VERSION "created by canmatrix"

NS_ :

BS_:

BU_:

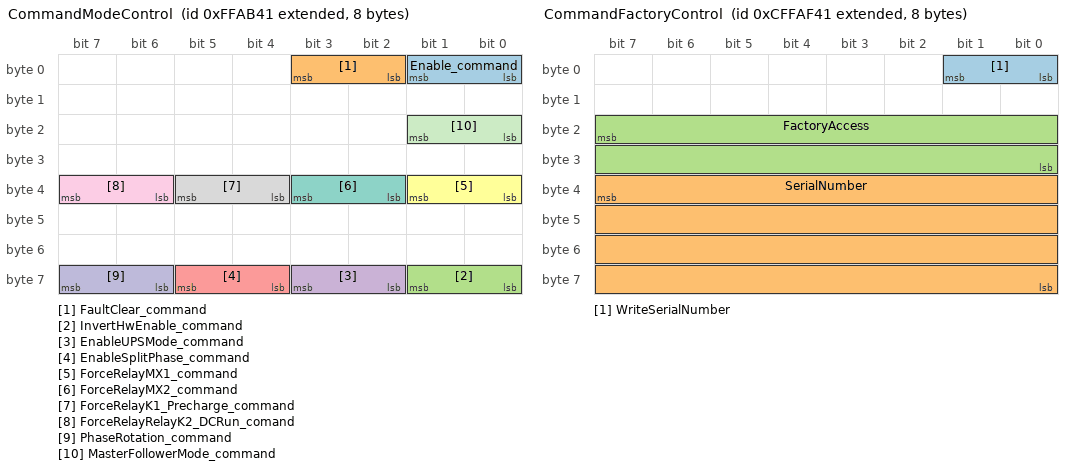
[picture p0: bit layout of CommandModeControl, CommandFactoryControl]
BO_ 2164239169 CommandModeControl: 8 Vector__XXX
 SG_ Enable_command : 1|2@0+ (1,0) [0|1] "" Vector__XXX
 SG_ FaultClear_command : 3|2@0+ (1,0) [0|1] "" Vector__XXX
 SG_ InvertHwEnable_command : 57|2@0+ (1,0) [0|1] "" Vector__XXX
 SG_ EnableUPSMode_command : 59|2@0+ (1,0) [0|1] "" Vector__XXX
 SG_ EnableSplitPhase_command : 61|2@0+ (1,0) [0|1] "" Vector__XXX
 SG_ ForceRelayMX1_command : 33|2@0+ (1,0) [0|1] "" Vector__XXX
 SG_ ForceRelayMX2_command : 35|2@0+ (1,0) [0|1] "" Vector__XXX
 SG_ ForceRelayK1_Precharge_command : 37|2@0+ (1,0) [0|1] "" Vector__XXX
 SG_ ForceRelayRelayK2_DCRun_comand : 39|2@0+ (1,0) [0|1] "" Vector__XXX
 SG_ PhaseRotation_command : 63|2@0+ (1,0) [0|1] "" Vector__XXX
 SG_ MasterFollowerMode_command : 17|2@0+ (1,0) [0|1] "" Vector__XXX

BO_ 2365566017 CommandPower: 8 Vector__XXX
 SG_ "RealPower command" : 7|32@0- (1,0) [-90000|90000] "W" Vector__XXX
 SG_ ReactivePower_command : 39|32@0- (1,0) [-90000|90000] "VA" Vector__XXX

BO_ 2365566529 CommandVF: 8 Vector__XXX
 SG_ Voltage_command : 7|16@0+ (0.1,0) [10|500] "Vrms" Vector__XXX
 SG_ Frequency_command : 23|16@0+ (0.1,0) [45|65] "Hz" Vector__XXX

BO_ 2365573878 MasterMeasuredPower: 8 Vector__XXX
 SG_ RealPower_measured : 7|32@0- (1,0) [0|1] "W" Vector__XXX
 SG_ ReactivePower_measured : 39|32@0- (1,0) [0|1] "VA" Vector__XXX

BO_ 2365566785 CommandFactoryControl: 8 Vector__XXX
 SG_ WriteSerialNumber : 1|2@0+ (1,0) [0|1] "" Vector__XXX
 SG_ SerialNumber : 39|32@0+ (1,0) [0|1] "" Vector__XXX
 SG_ FactoryAccess : 23|16@0+ (1,0) [0|1] "" Vector__XXX

BO_ 2365565505 CommandSetNVParam: 8 Vector__XXX
 SG_ CommandSetNVParam_MUX M  : 7|16@0- (1,0) [0|1] "" Vector__XXX
 SG_ Dummy m0  : 23|16@0+ (1,0) [0|1] "" Vector__XXX
 SG_ VUnder50pct m1  : 23|16@0+ (1,0) [1|30000] "ms" Vector__XXX
 SG_ V50to88pct m1  : 39|16@0+ (1,0) [1|30000] "ms" Vector__XXX
 SG_ V110to120pct m1  : 55|16@0+ (1,0) [1|30000] "ms" Vector__XXX
 SG_ VOver120 m2  : 23|16@0+ (1,0) [1|30000] "" Vector__XXX
 SG_ FreqHi m3  : 23|16@0+ (0.1,0) [40|70] "Hz" Vector__XXX
 SG_ FreqLo m3  : 39|16@0+ (0.1,0) [40|70] "Hz" Vector__XXX
 SG_ FreqVeryLo m3  : 55|16@0+ (0.1,0) [40|70] "Hz" Vector__XXX
 SG_ FreqVeryLo m4  : 23|16@0+ (1,0) [160|160] "ms" Vector__XXX
 SG_ FreqLo m4  : 39|16@0+ (1,0) [1|30000] "ms" Vector__XXX
 SG_ FreqHi m4  : 55|16@0+ (1,0) [160|160] "ms" Vector__XXX
 SG_ NodeID m5  : 23|8@0+ (1,0) [0|247] "" Vector__XXX
 SG_ SA_Mask m5  : 31|8@0+ (1,0) [0|1] "" Vector__XXX
 SG_ Baudrate m5  : 39|4@0+ (1,0) [0|3] "" Vector__XXX
 SG_ ThermalOverload m6  : 17|2@0+ (1,0) [0|1] "" Vector__XXX
 SG_ MX1Open m7  : 23|16@0+ (1,0) [0|5000] "ms" Vector__XXX
 SG_ MX1Close m7  : 39|16@0+ (1,0) [0|2000] "ms" Vector__XXX
 SG_ MX2Open m7  : 55|16@0+ (1,0) [0|1] "ms" Vector__XXX
 SG_ MX2Close m8  : 23|16@0+ (1,0) [0|2000] "ms" Vector__XXX
 SG_ K1Open m8  : 39|16@0+ (1,0) [0|2000] "ms" Vector__XXX
 SG_ K1Close m8  : 55|16@0+ (1,0) [0|2000] "ms" Vector__XXX
 SG_ K2Open m10  : 23|16@0+ (1,0) [0|2000] "ms" Vector__XXX
 SG_ K2Close m10  : 39|16@0+ (1,0) [0|2000] "ms" Vector__XXX

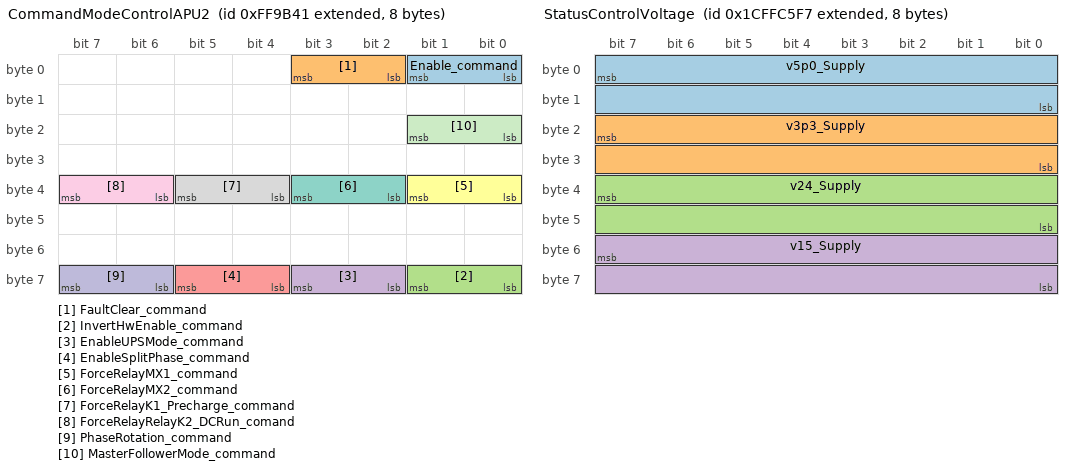
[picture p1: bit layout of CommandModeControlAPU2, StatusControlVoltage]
BO_ 2164235073 CommandModeControlAPU2: 8 Vector__XXX
 SG_ Enable_command : 1|2@0+ (1,0) [0|1] "" Vector__XXX
 SG_ FaultClear_command : 3|2@0+ (1,0) [0|1] "" Vector__XXX
 SG_ InvertHwEnable_command : 57|2@0+ (1,0) [0|1] "" Vector__XXX
 SG_ EnableUPSMode_command : 59|2@0+ (1,0) [0|1] "" Vector__XXX
 SG_ EnableSplitPhase_command : 61|2@0+ (1,0) [0|1] "" Vector__XXX
 SG_ ForceRelayMX1_command : 33|2@0+ (1,0) [0|1] "" Vector__XXX
 SG_ ForceRelayMX2_command : 35|2@0+ (1,0) [0|1] "" Vector__XXX
 SG_ ForceRelayK1_Precharge_command : 37|2@0+ (1,0) [0|1] "" Vector__XXX
 SG_ ForceRelayRelayK2_DCRun_comand : 39|2@0+ (1,0) [0|1] "" Vector__XXX
 SG_ PhaseRotation_command : 63|2@0+ (1,0) [0|1] "" Vector__XXX
 SG_ MasterFollowerMode_command : 17|2@0+ (1,0) [0|1] "" Vector__XXX

BO_ 2365561921 CommandPowerAPU2: 8 Vector__XXX
 SG_ RealPower_command : 7|32@0- (1,0) [-90000|90000] "W" Vector__XXX
 SG_ ReactivePower_command : 39|32@0- (1,0) [-90000|90000] "VA" Vector__XXX

BO_ 2365562433 CommandVFAPU2: 8 Vector__XXX
 SG_ Voltage_command : 7|16@0+ (0.1,0) [10|500] "Vrms" Vector__XXX
 SG_ Frequency_command : 23|16@0+ (0.1,0) [45|65] "Hz" Vector__XXX

BO_ 2365573879 MasterMeasuredPowerAPU2: 8 Vector__XXX
 SG_ RealPower_measured : 7|32@0- (1,0) [0|1] "W" Vector__XXX
 SG_ ReactivePower_measured : 39|32@0- (1,0) [0|1] "VA" Vector__XXX

BO_ 2365573879 StatusMeasuredPower: 8 Vector__XXX
 SG_ RealPower_measured : 7|32@0- (1,0) [0|1] "W" Vector__XXX
 SG_ ReactivePower_measured : 39|32@0- (1,0) [0|1] "VA" Vector__XXX

BO_ 2566898935 StatusCommandedPower: 8 Vector__XXX
 SG_ RealPower_echo : 7|32@0- (1,0) [0|1] "W" Vector__XXX
 SG_ ReactivePower_echo : 39|32@0- (1,0) [0|1] "VA" Vector__XXX

BO_ 2365572087 StatusBits: 8 Vector__XXX
 SG_ State_status : 3|4@0+ (1,0) [0|7] "" Vector__XXX
 SG_ MX2Permissive_status : 19|2@0+ (1,0) [0|1] "" Vector__XXX
 SG_ PowerAvailAC_status : 11|2@0+ (1,0) [0|1] "" Vector__XXX
 SG_ PowerAvailDC_status : 13|2@0+ (1,0) [0|1] "" Vector__XXX
 SG_ PowerCircuitEnabled_status : 15|2@0+ (1,0) [0|1] "" Vector__XXX
 SG_ HardwareEnable_status : 9|2@0+ (1,0) [0|1] "" Vector__XXX
 SG_ Enable_echo : 5|2@0+ (1,0) [0|1] "" Vector__XXX
 SG_ FaultClr_echo : 7|2@0+ (1,0) [0|1] "" Vector__XXX
 SG_ MessageValidModeControl_status : 25|2@0+ (1,0) [0|1] "" Vector__XXX
 SG_ MX1Permissive_status : 17|2@0+ (1,0) [0|1] "" Vector__XXX
 SG_ K2DCRunPermissive_status : 23|2@0+ (1,0) [0|1] "" Vector__XXX
 SG_ K1PrechargePermissive_status : 21|2@0+ (1,0) [0|1] "" Vector__XXX
 SG_ MessageValidPowerCMD_status : 27|2@0+ (1,0) [0|1] "" Vector__XXX
 SG_ MessageValidVF_status : 29|2@0+ (1,0) [0|1] "" Vector__XXX
 SG_ CANbus_status : 31|2@0+ (1,0) [0|1] "" Vector__XXX
 SG_ EnableUPSMode_echo : 33|2@0+ (1,0) [0|1] "" Vector__XXX
 SG_ EnableSplitPhase_echo : 35|2@0+ (1,0) [0|1] "" Vector__XXX
 SG_ PhaseRotation_status : 37|2@0+ (1,0) [0|1] "" Vector__XXX
 SG_ LineVoltageDetected_status : 39|2@0+ (1,0) [0|1] "" Vector__XXX
 SG_ PhaseRotation_echo : 41|2@0+ (1,0) [0|1] "" Vector__XXX

BO_ 2634008055 StatusControlVoltage: 8 Vector__XXX
 SG_ v5p0_Supply : 7|16@0- (0.01,0) [0|1] "V" Vector__XXX
 SG_ v3p3_Supply : 23|16@0- (0.01,0) [0|1] "V" Vector__XXX
 SG_ v24_Supply : 39|16@0- (0.01,0) [0|1] "V" Vector__XXX
 SG_ v15_Supply : 55|16@0- (0.01,0) [0|1] "V" Vector__XXX

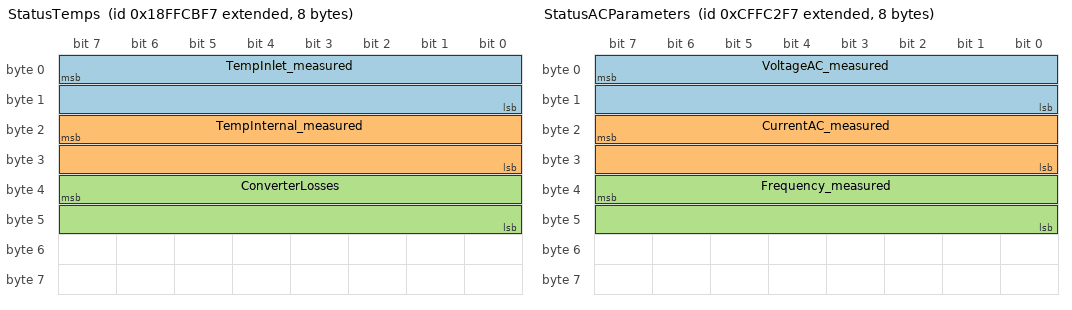
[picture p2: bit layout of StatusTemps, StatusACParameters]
BO_ 2566900727 StatusTemps: 8 Vector__XXX
 SG_ TempInlet_measured : 7|16@0- (0.1,0) [0|1] "C" Vector__XXX
 SG_ TempInternal_measured : 23|16@0- (0.1,0) [0|1] "C" Vector__XXX
 SG_ ConverterLosses : 39|16@0+ (1,0) [0|1] "W" Vector__XXX

BO_ 2365573367 StatusFaults: 8 Vector__XXX
 SG_ BridgeAVoltageOk_status : 59|1@0+ (1,0) [0|1] "" Vector__XXX
 SG_ OvercurrentAC_status : 3|2@0+ (1,0) [0|1] "" Vector__XXX
 SG_ BridgeBVoltageOk_status : 43|1@0+ (1,0) [0|1] "" Vector__XXX
 SG_ OvervoltageDC_status : 9|2@0+ (1,0) [0|1] "" Vector__XXX
 SG_ OvertempPowerDevice_status : 15|2@0+ (1,0) [0|1] "" Vector__XXX
 SG_ OvertempInternal_status : 13|2@0+ (1,0) [0|1] "" Vector__XXX
 SG_ LossValidControlMessage_status : 23|4@0+ (1,0) [0|1] "" Vector__XXX
 SG_ UndervoltageDC_status : 11|2@0+ (1,0) [0|1] "" Vector__XXX
 SG_ ControlHardwareFail_status : 19|4@0+ (1,0) [0|1] "" Vector__XXX
 SG_ OvercurrentDC_status : 7|2@0+ (1,0) [0|1] "" Vector__XXX
 SG_ GeneralFault_status : 1|2@0+ (1,0) [0|1] "" Vector__XXX
 SG_ LossOfAC_status : 5|2@0+ (1,0) [0|1] "" Vector__XXX
 SG_ EStopShutdown_status : 25|2@0+ (1,0) [0|1] "" Vector__XXX
 SG_ BridgeAFault_status : 58|3@0+ (1,0) [0|1] "" Vector__XXX
 SG_ BridgeBFault_status : 42|3@0+ (1,0) [0|1] "" Vector__XXX
 SG_ IllegalTransition_status : 27|2@0+ (1,0) [0|1] "" Vector__XXX
 SG_ InvalidEEHeader_status : 29|2@0+ (1,0) [0|1] "" Vector__XXX
 SG_ InvalidEESection_status : 31|2@0+ (1,0) [0|1] "" Vector__XXX
 SG_ ThermalOverload : 33|2@0+ (1,0) [0|1] "" Vector__XXX

BO_ 2365571831 StatusACParameters: 8 Vector__XXX
 SG_ VoltageAC_measured : 7|16@0- (0.1,0) [0|1] "V" Vector__XXX
 SG_ CurrentAC_measured : 23|16@0- (1,0) [0|1] "A" Vector__XXX
 SG_ Frequency_measured : 39|16@0- (0.1,0) [0|1] "Hz" Vector__XXX

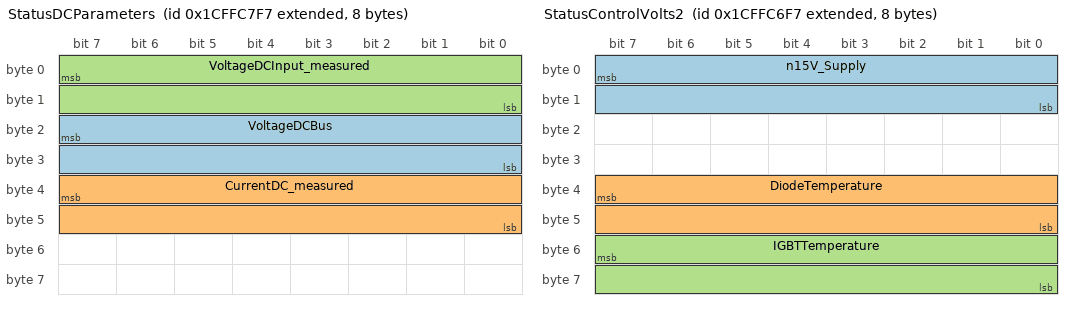
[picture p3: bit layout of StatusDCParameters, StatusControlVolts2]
BO_ 2634008567 StatusDCParameters: 8 Vector__XXX
 SG_ VoltageDCBus : 23|16@0- (1,0) [0|1] "V" Vector__XXX
 SG_ CurrentDC_measured : 39|16@0- (1,0) [0|1] "A" Vector__XXX
 SG_ VoltageDCInput_measured : 7|16@0- (1,0) [0|1] "V" Vector__XXX

BO_ 2634008311 StatusControlVolts2: 8 Vector__XXX
 SG_ n15V_Supply : 7|16@0- (0.01,0) [0|1] "V" Vector__XXX
 SG_ DiodeTemperature : 39|16@0+ (1,0) [0|1] "C" Vector__XXX
 SG_ IGBTTemperature : 55|16@0+ (1,0) [0|1] "C" Vector__XXX

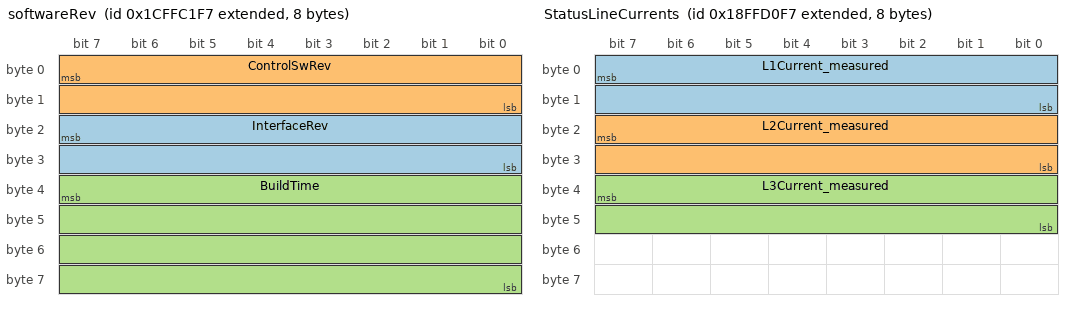
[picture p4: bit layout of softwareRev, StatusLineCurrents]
BO_ 2634007031 softwareRev: 8 Vector__XXX
 SG_ InterfaceRev : 23|16@0+ (0.01,0) [0|1] "" Vector__XXX
 SG_ ControlSwRev : 7|16@0+ (0.01,0) [0|1] "" Vector__XXX
 SG_ BuildTime : 39|32@0+ (1,0) [0|1] "" Vector__XXX

BO_ 2566900215 StatusCommandVF: 8 Vector__XXX
 SG_ Voltage_echo : 7|16@0+ (0.1,0) [0|1] "Vrms" Vector__XXX
 SG_ Frequency_echo : 23|16@0+ (0.1,0) [0|1] "Hz" Vector__XXX

BO_ 2634009847 serialNumber: 8 Vector__XXX
 SG_ SerialNumber : 7|32@0+ (1,0) [0|1] "" Vector__XXX

BO_ 2634010103 softwareRevHash: 8 Vector__XXX
 SG_ Hash : 7|28@0+ (1,0) [0|1] "" Vector__XXX

BO_ 2634000887 StatusNVParam: 8 Vector__XXX
 SG_ StatusNVParam_MUX M  : 7|16@0- (1,0) [0|1] "" Vector__XXX
 SG_ Dummy m0  : 23|16@0+ (1,0) [5|10] "" Vector__XXX
 SG_ VUnder50pct m1  : 23|16@0+ (1,0) [1|30000] "ms" Vector__XXX
 SG_ V50to88pct m1  : 39|16@0+ (1,0) [1|30000] "ms" Vector__XXX
 SG_ V110to120pct m1  : 55|16@0+ (1,0) [1|30000] "ms" Vector__XXX
 SG_ VOver120 m2  : 23|16@0+ (1,0) [1|30000] "" Vector__XXX
 SG_ FreqHi m3  : 23|16@0+ (0.1,0) [40|70] "Hz" Vector__XXX
 SG_ FreqLo m3  : 39|16@0+ (0.1,0) [40|70] "Hz" Vector__XXX
 SG_ FreqVeryLo m3  : 55|16@0+ (0.1,0) [40|70] "Hz" Vector__XXX
 SG_ FreqVeryLo m4  : 23|16@0+ (1,0) [160|160] "ms" Vector__XXX
 SG_ FreqLo m4  : 39|16@0+ (1,0) [1|30000] "ms" Vector__XXX
 SG_ FreqHi m4  : 55|16@0+ (1,0) [160|160] "ms" Vector__XXX
 SG_ StatusNodeID m5  : 23|8@0+ (1,0) [0|247] "" Vector__XXX
 SG_ StatusSA_Mask m5  : 31|8@0+ (1,0) [0|1] "" Vector__XXX
 SG_ StatusBaudrate m5  : 39|4@0+ (1,0) [0|3] "" Vector__XXX
 SG_ StatusThermalOverload m6  : 17|2@0+ (1,0) [0|1] "" Vector__XXX
 SG_ StatusMX1Open m7  : 23|16@0+ (1,0) [0|5000] "ms" Vector__XXX
 SG_ StatusMX1Close m7  : 39|16@0+ (1,0) [0|2000] "ms" Vector__XXX
 SG_ StatusMX2Open m7  : 55|16@0+ (1,0) [0|1] "ms" Vector__XXX
 SG_ StatusMX2Close m8  : 23|16@0+ (1,0) [0|2000] "ms" Vector__XXX
 SG_ StatusK1Open m8  : 39|16@0+ (1,0) [0|2000] "ms" Vector__XXX
 SG_ StatusK1Close m8  : 55|16@0+ (1,0) [0|2000] "ms" Vector__XXX
 SG_ StatusK2Open m9  : 23|16@0+ (1,0) [0|2000] "ms" Vector__XXX
 SG_ StatusK2Close m9  : 39|16@0+ (1,0) [0|2000] "ms" Vector__XXX

BO_ 2566902007 StatusLineCurrents: 8 Vector__XXX
 SG_ L1Current_measured : 7|16@0+ (1,0) [0|1] "A" Vector__XXX
 SG_ L2Current_measured : 23|16@0+ (1,0) [0|1] "A" Vector__XXX
 SG_ L3Current_measured : 39|16@0+ (1,0) [0|1] "A" Vector__XXX

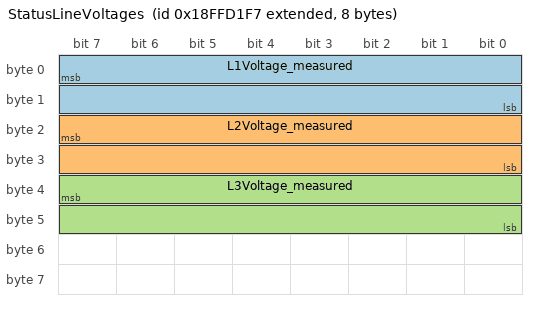
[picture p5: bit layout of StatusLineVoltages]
BO_ 2566902263 StatusLineVoltages: 8 Vector__XXX
 SG_ L1Voltage_measured : 7|16@0+ (0.1,0) [0|1] "Vrms" Vector__XXX
 SG_ L2Voltage_measured : 23|16@0+ (0.1,0) [0|1] "Vrms" Vector__XXX
 SG_ L3Voltage_measured : 39|16@0+ (0.1,0) [0|1] "Vrms" Vector__XXX

CM_ BO_ 2164239169  "Operational commands are received by the module via control bits within this message.";
CM_ BO_ 2365566017  "Sets the desired real (P) and reactive (Q) power levels for the module to follow while in the GRID FOLLOWING mode.";
CM_ BO_ 2365566529  "Sets the desired voltage and frequency for the module to produce while in the GRID FORMING mode.  In addition, while in the READY and GRID FOLLOWING modes, this message is used to set the nominal voltage levels for detection of acceptable AC line voltage.";
CM_ BO_ 2365573878  "Returns the actual measured power.";
CM_ BO_ 2365565505  "Provides access to configure non-volatile parameters.  Note that these parameters can only be set when the inverter's power stage is disabled (PowerCircuitEnabled_status in StatusBits message is 'Disabled.')";
CM_ BO_ 2164235073  "Operational commands are received by the module via control bits within this message.";
CM_ BO_ 2365561921  "Sets the desired real (P) and reactive (Q) power levels for the module to follow while in the GRID FOLLOWING mode.";
CM_ BO_ 2365562433  "Sets the desired voltage and frequency for the module to produce while in the GRID FORMING mode.  In addition, while in the READY and GRID FOLLOWING modes, this message is used to set the nominal voltage levels for detection of acceptable AC line voltage.";
CM_ BO_ 2365573879  "Returns the actual measured power.";
CM_ BO_ 2365573879  "Returns the actual measured power.";
CM_ BO_ 2566898935  "Echoes the commanded power (P&Q) as received in CommandPQ.";
CM_ BO_ 2365572087  "Bits representing the status of the power module.";
CM_ BO_ 2634008055  "Lists present voltage of each power supply on the control board (24V, 15V, 5V, and 3.3V.)";
CM_ BO_ 2566900727  "Returns the inlet water temperature to the module as well as module internal ambient temperature.";
CM_ BO_ 2365573367  "Fault bits.";
CM_ BO_ 2365571831  "RMS AC Voltage, current, and frequency measured by line A, B and C feedbacks.";
CM_ BO_ 2634008567  "Measured (boosted) DC Bus voltage, DC Current, and estimated DC Input voltage.";
CM_ BO_ 2634008311  "Present voltage of the -15V power supply on the control board.";
CM_ BO_ 2634007031  "Software revision.";
CM_ BO_ 2566900215  "Echoes the voltage and frequency commands from commandVF.";
CM_ BO_ 2634009847  "Serial number of the power module.";
CM_ BO_ 2634010103  "Unique software revision identification hashcode.";
CM_ BO_ 2634000887  "Echos back parameter values.";
CM_ BO_ 2566902007  "Measured RMS line currents.";
CM_ BO_ 2566902263  "Measured RMS line voltages.";

BA_DEF_ BO_ "GenMsgCycleTime" INT 0 65535;
BA_DEF_ SG_ "GenSigStartValue" FLOAT -3.4E+038 3.4E+038;

BA_ "GenMsgCycleTime" BO_ 2365573879 100;
BA_ "GenMsgCycleTime" BO_ 2566898935 100;
BA_ "GenMsgCycleTime" BO_ 2365572087 100;
BA_ "GenMsgCycleTime" BO_ 2634008055 100;
BA_ "GenMsgCycleTime" BO_ 2566900727 100;
BA_ "GenMsgCycleTime" BO_ 2365573367 100;
BA_ "GenMsgCycleTime" BO_ 2365571831 100;
BA_ "GenMsgCycleTime" BO_ 2634008567 100;
BA_ "GenMsgCycleTime" BO_ 2634008311 100;
BA_ "GenMsgCycleTime" BO_ 2566900215 100;
BA_ "GenMsgCycleTime" BO_ 2566902007 100;
BA_ "GenMsgCycleTime" BO_ 2566902263 100;

BA_ "GenSigStartValue" SG_ 2164239169 Enable_command 0.0;
BA_ "GenSigStartValue" SG_ 2164239169 FaultClear_command 0.0;
BA_ "GenSigStartValue" SG_ 2164239169 InvertHwEnable_command 0.0;
BA_ "GenSigStartValue" SG_ 2164239169 EnableUPSMode_command 0.0;
BA_ "GenSigStartValue" SG_ 2164239169 EnableSplitPhase_command 0.0;
BA_ "GenSigStartValue" SG_ 2164239169 ForceRelayMX1_command 0.0;
BA_ "GenSigStartValue" SG_ 2164239169 ForceRelayMX2_command 0.0;
BA_ "GenSigStartValue" SG_ 2164239169 ForceRelayK1_Precharge_command 0.0;
BA_ "GenSigStartValue" SG_ 2164239169 ForceRelayRelayK2_DCRun_comand 0.0;
BA_ "GenSigStartValue" SG_ 2164239169 PhaseRotation_command 0.0;
BA_ "GenSigStartValue" SG_ 2164239169 MasterFollowerMode_command 0.0;
BA_ "GenSigStartValue" SG_ 2365566017 "RealPower command" 0.0;
BA_ "GenSigStartValue" SG_ 2365566017 ReactivePower_command 0.0;
BA_ "GenSigStartValue" SG_ 2365566529 Voltage_command 2400.0;
BA_ "GenSigStartValue" SG_ 2365566529 Frequency_command 500.0;
BA_ "GenSigStartValue" SG_ 2365573878 RealPower_measured 0.0;
BA_ "GenSigStartValue" SG_ 2365573878 ReactivePower_measured 0.0;
BA_ "GenSigStartValue" SG_ 2365566785 WriteSerialNumber 0.0;
BA_ "GenSigStartValue" SG_ 2365566785 SerialNumber 0.0;
BA_ "GenSigStartValue" SG_ 2365566785 FactoryAccess 0.0;
BA_ "GenSigStartValue" SG_ 2365565505 Dummy 0.0;
BA_ "GenSigStartValue" SG_ 2365565505 VUnder50pct 160.0;
BA_ "GenSigStartValue" SG_ 2365565505 V50to88pct 2000.0;
BA_ "GenSigStartValue" SG_ 2365565505 V110to120pct 1000.0;
BA_ "GenSigStartValue" SG_ 2365565505 VOver120 160.0;
BA_ "GenSigStartValue" SG_ 2365565505 FreqHi 605.0;
BA_ "GenSigStartValue" SG_ 2365565505 FreqLo 598.0;
BA_ "GenSigStartValue" SG_ 2365565505 FreqVeryLo 570.0;
BA_ "GenSigStartValue" SG_ 2365565505 FreqVeryLo 160.0;
BA_ "GenSigStartValue" SG_ 2365565505 FreqLo 160.0;
BA_ "GenSigStartValue" SG_ 2365565505 FreqHi 160.0;
BA_ "GenSigStartValue" SG_ 2365565505 NodeID 247.0;
BA_ "GenSigStartValue" SG_ 2365565505 SA_Mask 65.0;
BA_ "GenSigStartValue" SG_ 2365565505 Baudrate 2.0;
BA_ "GenSigStartValue" SG_ 2365565505 ThermalOverload 0.0;
BA_ "GenSigStartValue" SG_ 2365565505 MX1Open 100.0;
BA_ "GenSigStartValue" SG_ 2365565505 MX1Close 100.0;
BA_ "GenSigStartValue" SG_ 2365565505 MX2Open 0.0;
BA_ "GenSigStartValue" SG_ 2365565505 MX2Close 0.0;
BA_ "GenSigStartValue" SG_ 2365565505 K1Open 0.0;
BA_ "GenSigStartValue" SG_ 2365565505 K1Close 0.0;
BA_ "GenSigStartValue" SG_ 2365565505 K2Open 0.0;
BA_ "GenSigStartValue" SG_ 2365565505 K2Close 0.0;
BA_ "GenSigStartValue" SG_ 2164235073 Enable_command 0.0;
BA_ "GenSigStartValue" SG_ 2164235073 FaultClear_command 0.0;
BA_ "GenSigStartValue" SG_ 2164235073 InvertHwEnable_command 0.0;
BA_ "GenSigStartValue" SG_ 2164235073 EnableUPSMode_command 0.0;
BA_ "GenSigStartValue" SG_ 2164235073 EnableSplitPhase_command 0.0;
BA_ "GenSigStartValue" SG_ 2164235073 ForceRelayMX1_command 0.0;
BA_ "GenSigStartValue" SG_ 2164235073 ForceRelayMX2_command 0.0;
BA_ "GenSigStartValue" SG_ 2164235073 ForceRelayK1_Precharge_command 0.0;
BA_ "GenSigStartValue" SG_ 2164235073 ForceRelayRelayK2_DCRun_comand 0.0;
BA_ "GenSigStartValue" SG_ 2164235073 PhaseRotation_command 0.0;
BA_ "GenSigStartValue" SG_ 2164235073 MasterFollowerMode_command 0.0;
BA_ "GenSigStartValue" SG_ 2365561921 RealPower_command 0.0;
BA_ "GenSigStartValue" SG_ 2365561921 ReactivePower_command 0.0;
BA_ "GenSigStartValue" SG_ 2365562433 Voltage_command 2400.0;
BA_ "GenSigStartValue" SG_ 2365562433 Frequency_command 500.0;
BA_ "GenSigStartValue" SG_ 2365573879 RealPower_measured 0.0;
BA_ "GenSigStartValue" SG_ 2365573879 ReactivePower_measured 0.0;
BA_ "GenSigStartValue" SG_ 2365573879 RealPower_measured 0.0;
BA_ "GenSigStartValue" SG_ 2365573879 ReactivePower_measured 0.0;
BA_ "GenSigStartValue" SG_ 2566898935 RealPower_echo 0.0;
BA_ "GenSigStartValue" SG_ 2566898935 ReactivePower_echo 0.0;
BA_ "GenSigStartValue" SG_ 2365572087 State_status 0.0;
BA_ "GenSigStartValue" SG_ 2365572087 MX2Permissive_status 0.0;
BA_ "GenSigStartValue" SG_ 2365572087 PowerAvailAC_status 0.0;
BA_ "GenSigStartValue" SG_ 2365572087 PowerAvailDC_status 0.0;
BA_ "GenSigStartValue" SG_ 2365572087 PowerCircuitEnabled_status 0.0;
BA_ "GenSigStartValue" SG_ 2365572087 HardwareEnable_status 0.0;
BA_ "GenSigStartValue" SG_ 2365572087 Enable_echo 0.0;
BA_ "GenSigStartValue" SG_ 2365572087 FaultClr_echo 0.0;
BA_ "GenSigStartValue" SG_ 2365572087 MessageValidModeControl_status 0.0;
BA_ "GenSigStartValue" SG_ 2365572087 MX1Permissive_status 0.0;
BA_ "GenSigStartValue" SG_ 2365572087 K2DCRunPermissive_status 0.0;
BA_ "GenSigStartValue" SG_ 2365572087 K1PrechargePermissive_status 0.0;
BA_ "GenSigStartValue" SG_ 2365572087 MessageValidPowerCMD_status 0.0;
BA_ "GenSigStartValue" SG_ 2365572087 MessageValidVF_status 0.0;
BA_ "GenSigStartValue" SG_ 2365572087 CANbus_status 0.0;
BA_ "GenSigStartValue" SG_ 2365572087 EnableUPSMode_echo 0.0;
BA_ "GenSigStartValue" SG_ 2365572087 EnableSplitPhase_echo 0.0;
BA_ "GenSigStartValue" SG_ 2365572087 PhaseRotation_status 0.0;
BA_ "GenSigStartValue" SG_ 2365572087 LineVoltageDetected_status 0.0;
BA_ "GenSigStartValue" SG_ 2365572087 PhaseRotation_echo 0.0;
BA_ "GenSigStartValue" SG_ 2634008055 v5p0_Supply 0.0;
BA_ "GenSigStartValue" SG_ 2634008055 v3p3_Supply 0.0;
BA_ "GenSigStartValue" SG_ 2634008055 v24_Supply 0.0;
BA_ "GenSigStartValue" SG_ 2634008055 v15_Supply 0.0;
BA_ "GenSigStartValue" SG_ 2566900727 TempInlet_measured 0.0;
BA_ "GenSigStartValue" SG_ 2566900727 TempInternal_measured 0.0;
BA_ "GenSigStartValue" SG_ 2566900727 ConverterLosses 0.0;
BA_ "GenSigStartValue" SG_ 2365573367 BridgeAVoltageOk_status 0.0;
BA_ "GenSigStartValue" SG_ 2365573367 OvercurrentAC_status 0.0;
BA_ "GenSigStartValue" SG_ 2365573367 BridgeBVoltageOk_status 0.0;
BA_ "GenSigStartValue" SG_ 2365573367 OvervoltageDC_status 0.0;
BA_ "GenSigStartValue" SG_ 2365573367 OvertempPowerDevice_status 0.0;
BA_ "GenSigStartValue" SG_ 2365573367 OvertempInternal_status 0.0;
BA_ "GenSigStartValue" SG_ 2365573367 LossValidControlMessage_status 0.0;
BA_ "GenSigStartValue" SG_ 2365573367 UndervoltageDC_status 0.0;
BA_ "GenSigStartValue" SG_ 2365573367 ControlHardwareFail_status 0.0;
BA_ "GenSigStartValue" SG_ 2365573367 OvercurrentDC_status 0.0;
BA_ "GenSigStartValue" SG_ 2365573367 GeneralFault_status 0.0;
BA_ "GenSigStartValue" SG_ 2365573367 LossOfAC_status 0.0;
BA_ "GenSigStartValue" SG_ 2365573367 EStopShutdown_status 0.0;
BA_ "GenSigStartValue" SG_ 2365573367 BridgeAFault_status 0.0;
BA_ "GenSigStartValue" SG_ 2365573367 BridgeBFault_status 0.0;
BA_ "GenSigStartValue" SG_ 2365573367 IllegalTransition_status 0.0;
BA_ "GenSigStartValue" SG_ 2365573367 InvalidEEHeader_status 0.0;
BA_ "GenSigStartValue" SG_ 2365573367 InvalidEESection_status 0.0;
BA_ "GenSigStartValue" SG_ 2365573367 ThermalOverload 0.0;
BA_ "GenSigStartValue" SG_ 2365571831 VoltageAC_measured 0.0;
BA_ "GenSigStartValue" SG_ 2365571831 CurrentAC_measured 0.0;
BA_ "GenSigStartValue" SG_ 2365571831 Frequency_measured 0.0;
BA_ "GenSigStartValue" SG_ 2634008567 VoltageDCBus 0.0;
BA_ "GenSigStartValue" SG_ 2634008567 CurrentDC_measured 0.0;
BA_ "GenSigStartValue" SG_ 2634008567 VoltageDCInput_measured 0.0;
BA_ "GenSigStartValue" SG_ 2634008311 n15V_Supply 0.0;
BA_ "GenSigStartValue" SG_ 2634008311 DiodeTemperature 0.0;
BA_ "GenSigStartValue" SG_ 2634008311 IGBTTemperature 0.0;
BA_ "GenSigStartValue" SG_ 2634007031 InterfaceRev 0.0;
BA_ "GenSigStartValue" SG_ 2634007031 ControlSwRev 0.0;
BA_ "GenSigStartValue" SG_ 2634007031 BuildTime 0.0;
BA_ "GenSigStartValue" SG_ 2566900215 Voltage_echo 0.0;
BA_ "GenSigStartValue" SG_ 2566900215 Frequency_echo 0.0;
BA_ "GenSigStartValue" SG_ 2634009847 SerialNumber 0.0;
BA_ "GenSigStartValue" SG_ 2634010103 Hash 0.0;
BA_ "GenSigStartValue" SG_ 2634000887 Dummy 0.0;
BA_ "GenSigStartValue" SG_ 2634000887 VUnder50pct 160.0;
BA_ "GenSigStartValue" SG_ 2634000887 V50to88pct 2000.0;
BA_ "GenSigStartValue" SG_ 2634000887 V110to120pct 1000.0;
BA_ "GenSigStartValue" SG_ 2634000887 VOver120 160.0;
BA_ "GenSigStartValue" SG_ 2634000887 FreqHi 605.0;
BA_ "GenSigStartValue" SG_ 2634000887 FreqLo 598.0;
BA_ "GenSigStartValue" SG_ 2634000887 FreqVeryLo 570.0;
BA_ "GenSigStartValue" SG_ 2634000887 FreqVeryLo 160.0;
BA_ "GenSigStartValue" SG_ 2634000887 FreqLo 160.0;
BA_ "GenSigStartValue" SG_ 2634000887 FreqHi 160.0;
BA_ "GenSigStartValue" SG_ 2634000887 StatusNodeID 247.0;
BA_ "GenSigStartValue" SG_ 2634000887 StatusSA_Mask 65.0;
BA_ "GenSigStartValue" SG_ 2634000887 StatusBaudrate 2.0;
BA_ "GenSigStartValue" SG_ 2634000887 StatusThermalOverload 0.0;
BA_ "GenSigStartValue" SG_ 2634000887 StatusMX1Open 100.0;
BA_ "GenSigStartValue" SG_ 2634000887 StatusMX1Close 100.0;
BA_ "GenSigStartValue" SG_ 2634000887 StatusMX2Open 0.0;
BA_ "GenSigStartValue" SG_ 2634000887 StatusMX2Close 0.0;
BA_ "GenSigStartValue" SG_ 2634000887 StatusK1Open 0.0;
BA_ "GenSigStartValue" SG_ 2634000887 StatusK1Close 0.0;
BA_ "GenSigStartValue" SG_ 2634000887 StatusK2Open 0.0;
BA_ "GenSigStartValue" SG_ 2634000887 StatusK2Close 0.0;
BA_ "GenSigStartValue" SG_ 2566902007 L1Current_measured 0.0;
BA_ "GenSigStartValue" SG_ 2566902007 L2Current_measured 0.0;
BA_ "GenSigStartValue" SG_ 2566902007 L3Current_measured 0.0;
BA_ "GenSigStartValue" SG_ 2566902263 L1Voltage_measured 0.0;
BA_ "GenSigStartValue" SG_ 2566902263 L2Voltage_measured 0.0;
BA_ "GenSigStartValue" SG_ 2566902263 L3Voltage_measured 0.0;

VAL_ 2164239169 Enable_command 0 "Disable" 1 "Enable" 2 "Error" 3 "N/A";
VAL_ 2164239169 FaultClear_command 0 "Normal" 1 "Clear Faults" 2 "Error" 3 "N/A";
VAL_ 2164239169 InvertHwEnable_command 0 "No invert" 1 "Invert" 2 "Error" 3 "N/A";
VAL_ 2164239169 EnableUPSMode_command 0 "Disable" 1 "Enable" 2 "Error" 3 "N/A";
VAL_ 2164239169 EnableSplitPhase_command 0 "Normal - Three Phase Mode" 1 "Enable Split Phase Mode" 2 "Error" 3 "N/A";
VAL_ 2164239169 ForceRelayMX1_command 0 "Normal" 1 "Force On" 2 "Error" 3 "N/A";
VAL_ 2164239169 ForceRelayMX2_command 0 "Normal" 1 "Force On" 2 "Error" 3 "N/A";
VAL_ 2164239169 ForceRelayK1_Precharge_command 0 "Normal" 1 "Force On" 2 "Error" 3 "N/A";
VAL_ 2164239169 ForceRelayRelayK2_DCRun_comand 0 "Normal" 1 "Force On" 2 "Error" 3 "N/A";
VAL_ 2164239169 PhaseRotation_command 0 "Negative" 1 "Positive" 2 "Error" 3 "N/A";
VAL_ 2164239169 MasterFollowerMode_command 0 "Master" 1 "Follower" 2 "Error" 3 "N/A";
VAL_ 2365566785 WriteSerialNumber 0 "Disable" 1 "Enable" 2 "Error" 3 "N/A";
VAL_ 2365565505 CommandSetNVParam_MUX 0 "Param0" 1 "LVM_ClearingTimes1" 2 "LVM_ClearingTimes2" 3 "LFM_Limits" 4 "LFM_ClearingTimes" 5 "J1939_Interface" 6 "Fault_Config" 7 "ContactorDelays1" 8 "ContactorDelays2" 10 "ContactorDelays3";
VAL_ 2365565505 Baudrate 0 "125K" 1 "250K" 2 "500K" 3 "1M";
VAL_ 2365565505 ThermalOverload 0 "Warning" 1 "Fault" 2 "Error" 3 "N/A";
VAL_ 2164235073 Enable_command 0 "Disable" 1 "Enable" 2 "Error" 3 "N/A";
VAL_ 2164235073 FaultClear_command 0 "Normal" 1 "Clear Faults" 2 "Error" 3 "N/A";
VAL_ 2164235073 InvertHwEnable_command 0 "No invert" 1 "Invert" 2 "Error" 3 "N/A";
VAL_ 2164235073 EnableUPSMode_command 0 "Disable" 1 "Enable" 2 "Error" 3 "N/A";
VAL_ 2164235073 EnableSplitPhase_command 0 "Normal - Three Phase Mode" 1 "Enable Split Phase Mode" 2 "Error" 3 "N/A";
VAL_ 2164235073 ForceRelayMX1_command 0 "Normal" 1 "Force On" 2 "Error" 3 "N/A";
VAL_ 2164235073 ForceRelayMX2_command 0 "Normal" 1 "Force On" 2 "Error" 3 "N/A";
VAL_ 2164235073 ForceRelayK1_Precharge_command 0 "Normal" 1 "Force On" 2 "Error" 3 "N/A";
VAL_ 2164235073 ForceRelayRelayK2_DCRun_comand 0 "Normal" 1 "Force On" 2 "Error" 3 "N/A";
VAL_ 2164235073 PhaseRotation_command 0 "Negative" 1 "Positive" 2 "Error" 3 "N/A";
VAL_ 2164235073 MasterFollowerMode_command 0 "Master" 1 "Follower" 2 "Error" 3 "N/A";
VAL_ 2365572087 State_status 0 "Power On Reset, and a quoted comma" 1 "Ready" 2 "Following" 3 "Fault" 4 "Forming" 5 "N/A" 6 "N/A" 7 "N/A" 8 "N/A" 9 "N/A" 10 "N/A" 11 "N/A" 12 "N/A" 13 "N/A" 14 "N/A" 15 "N/A";
VAL_ 2365572087 MX2Permissive_status 0 "Open" 1 "Closed" 2 "Error" 3 "N/A";
VAL_ 2365572087 PowerAvailAC_status 0 "None" 1 "Available" 2 "Error" 3 "N/A";
VAL_ 2365572087 PowerAvailDC_status 0 "None" 1 "Available" 2 "Error" 3 "N/A";
VAL_ 2365572087 PowerCircuitEnabled_status 0 "Disabled" 1 "Enabled" 2 "Error" 3 "N/A";
VAL_ 2365572087 HardwareEnable_status 0 "Not Active" 1 "Active" 2 "Error" 3 "N/A";
VAL_ 2365572087 Enable_echo 0 "Disable" 1 "Enable" 2 "Error" 3 "N/A";
VAL_ 2365572087 FaultClr_echo 0 "Normal" 1 "Clear Faults" 2 "Error" 3 "N/A";
VAL_ 2365572087 MessageValidModeControl_status 0 "Invalid" 1 "Valid" 2 "Error" 3 "N/A";
VAL_ 2365572087 MX1Permissive_status 0 "Open" 1 "Closed" 2 "Error" 3 "N/A";
VAL_ 2365572087 K2DCRunPermissive_status 0 "Open" 1 "Closed" 2 "Error" 3 "N/A";
VAL_ 2365572087 K1PrechargePermissive_status 0 "Open" 1 "Closed" 2 "Error" 3 "N/A";
VAL_ 2365572087 MessageValidPowerCMD_status 0 "Invalid" 1 "Valid" 2 "Error" 3 "N/A";
VAL_ 2365572087 MessageValidVF_status 0 "Invalid" 1 "Valid" 2 "Error" 3 "N/A";
VAL_ 2365572087 CANbus_status 0 "Normal" 1 "Warning" 3 "ErrorPassive" 4 "N/A";
VAL_ 2365572087 EnableUPSMode_echo 0 "Disable" 1 "Enable" 2 "Error" 3 "N/A";
VAL_ 2365572087 EnableSplitPhase_echo 0 "Normal - Three Phase Mode" 1 "Enable Split Phase Mode" 2 "Error" 3 "N/A";
VAL_ 2365572087 PhaseRotation_status 0 "Negative" 1 "Positive" 2 "Error" 3 "N/A";
VAL_ 2365572087 LineVoltageDetected_status 0 "No_Voltage" 1 "Voltage_Detected" 2 "Error" 3 "N/A";
VAL_ 2365572087 PhaseRotation_echo 0 "Negative" 1 "Positive" 2 "Error" 3 "N/A";
VAL_ 2365573367 BridgeAVoltageOk_status 0 "Normal" 1 "Fault Active" 2 "Error" 3 "N/A";
VAL_ 2365573367 OvercurrentAC_status 0 "Normal" 1 "Fault Active" 2 "Error" 3 "N/A";
VAL_ 2365573367 BridgeBVoltageOk_status 0 "Normal" 1 "Fault Active" 2 "Error" 3 "N/A";
VAL_ 2365573367 OvervoltageDC_status 0 "Normal" 1 "Fault Active" 2 "Error" 3 "N/A";
VAL_ 2365573367 OvertempPowerDevice_status 0 "Normal" 1 "Fault Active" 2 "Error" 3 "N/A";
VAL_ 2365573367 OvertempInternal_status 0 "Normal" 1 "Fault Active" 2 "Error" 3 "N/A";
VAL_ 2365573367 LossValidControlMessage_status 0 "Normal" 1 "Fault Active" 2 "Error" 3 "N/A";
VAL_ 2365573367 UndervoltageDC_status 0 "Normal" 1 "Fault Active" 2 "Error" 3 "N/A";
VAL_ 2365573367 ControlHardwareFail_status 0 "Normal" 1 "Fault Active" 2 "Error" 3 "N/A";
VAL_ 2365573367 OvercurrentDC_status 0 "Normal" 1 "Fault Active" 2 "Error" 3 "N/A";
VAL_ 2365573367 GeneralFault_status 0 "Normal" 1 "Fault Active" 2 "Error" 3 "N/A";
VAL_ 2365573367 LossOfAC_status 0 "Normal" 1 "Fault Active" 2 "Error" 3 "N/A";
VAL_ 2365573367 EStopShutdown_status 0 "Normal" 1 "Fault Active" 2 "Error" 3 "N/A";
VAL_ 2365573367 BridgeAFault_status 0 "Normal" 1 "FLT_A" 2 "N/A" 3 "FLT_C" 4 "OverVoltage" 5 "FLT_B" 6 "Overcurrent" 7 "5V";
VAL_ 2365573367 BridgeBFault_status 0 "Normal" 1 "FLT_A" 2 "N/A" 3 "FLT_C" 4 "OverVoltage" 5 "FLT_B" 6 "Overcurrent" 7 "5V";
VAL_ 2365573367 IllegalTransition_status 0 "Normal" 1 "Fault Active" 2 "Error" 3 "N/A";
VAL_ 2365573367 InvalidEEHeader_status 0 "Normal" 1 "Fault Active" 2 "Error" 3 "N/A";
VAL_ 2365573367 InvalidEESection_status 0 "Normal" 1 "Fault Active" 2 "Error" 3 "N/A";
VAL_ 2365573367 ThermalOverload 0 "Normal" 1 "Fault Active" 2 "Error" 3 "N/A";
VAL_ 2634000887 StatusNVParam_MUX 0 "ActParam0" 1 "ActLVM_ClearingTimes1" 2 "ActLVM_ClearingTimes2" 3 "ActLFM_Limits" 4 "ActLFM_ClearingTimes" 5 "StatusJ1939_Interface" 6 "StatusFault_Config" 7 "StatusContactorDelays1" 8 "StatusContactorDelays2" 9 "StatusContactorDelays3";
VAL_ 2634000887 StatusBaudrate 0 "125K" 1 "250K" 2 "500K" 3 "1M";
VAL_ 2634000887 StatusThermalOverload 0 "Warning" 1 "Fault" 2 "Error" 3 "N/A";
